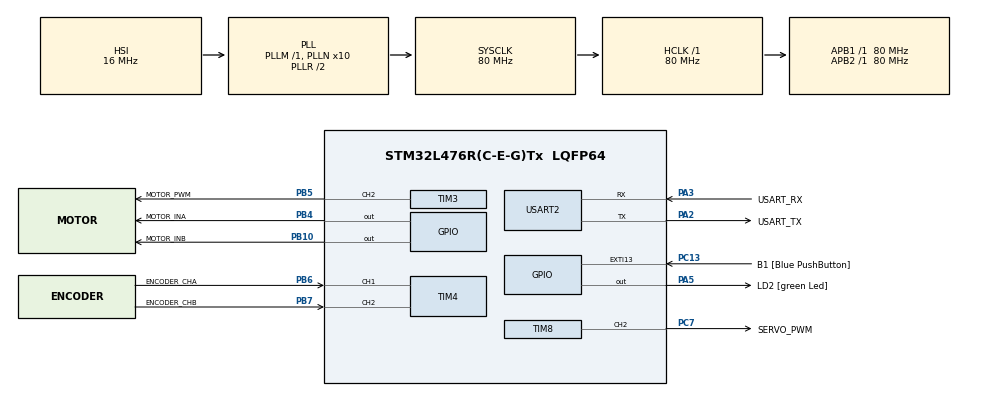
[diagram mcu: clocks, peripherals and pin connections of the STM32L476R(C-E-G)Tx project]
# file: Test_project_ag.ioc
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Dma.Request0=USART2_RX
Dma.Request1=USART2_TX
Dma.USART2_RX.0.Direction=DMA_PERIPH_TO_MEMORY
Dma.USART2_RX.0.Instance=DMA1_Channel6
Dma.USART2_RX.0.MemDataAlignment=DMA_MDATAALIGN_BYTE
Dma.USART2_RX.0.MemInc=DMA_MINC_ENABLE
Dma.USART2_RX.0.Mode=DMA_CIRCULAR
Dma.USART2_RX.0.PeriphDataAlignment=DMA_PDATAALIGN_BYTE
Dma.USART2_RX.0.PeriphInc=DMA_PINC_DISABLE
Dma.USART2_RX.0.Priority=DMA_PRIORITY_VERY_HIGH
Dma.USART2_TX.1.Direction=DMA_MEMORY_TO_PERIPH
Dma.USART2_TX.1.Instance=DMA1_Channel7
Dma.USART2_TX.1.MemDataAlignment=DMA_MDATAALIGN_BYTE
Dma.USART2_TX.1.MemInc=DMA_MINC_ENABLE
Dma.USART2_TX.1.Mode=DMA_NORMAL
Dma.USART2_TX.1.PeriphDataAlignment=DMA_PDATAALIGN_BYTE
Dma.USART2_TX.1.PeriphInc=DMA_PINC_DISABLE
Dma.USART2_TX.1.Priority=DMA_PRIORITY_HIGH
Mcu.Family=STM32L4
Mcu.Name=STM32L476R(C-E-G)Tx
Mcu.Package=LQFP64
Mcu.UserConstants=PUB_COUNT_MAX,9999;SERVO_PWM_COUNT_MAX,39999;SERVO_PRESCALER,39;ENC_COUNT_MAX,999;ENC_PRESCALER,79;RASPI_UART_BAUD,1000000;PUB_PRESCALER,79;MOT_PWM_COUNT_MAX,4999
NVIC.DMA1_Channel6_IRQn=true\:0\:0\:false\:false\:true\:false\:true\:true
NVIC.DMA1_Channel7_IRQn=true\:0\:0\:false\:false\:true\:false\:true\:true
NVIC.EXTI15_10_IRQn=true\:0\:0\:false\:false\:true\:true\:true\:true
NVIC.PriorityGroup=NVIC_PRIORITYGROUP_4
NVIC.TIM1_UP_TIM16_IRQn=true\:0\:0\:false\:false\:true\:true\:true\:true
NVIC.TIM6_DAC_IRQn=true\:0\:0\:false\:false\:true\:true\:true\:true
NVIC.USART2_IRQn=true\:0\:0\:false\:false\:true\:true\:true\:true
PA13\ (JTMS-SWDIO).GPIO_Label=TMS
PA13\ (JTMS-SWDIO).Mode=Serial_Wire
PA13\ (JTMS-SWDIO).Signal=SYS_JTMS-SWDIO
PA14\ (JTCK-SWCLK).GPIO_Label=TCK
PA14\ (JTCK-SWCLK).Mode=Serial_Wire
PA14\ (JTCK-SWCLK).Signal=SYS_JTCK-SWCLK
PA2.GPIO_Label=USART_TX
PA2.GPIO_Mode=GPIO_MODE_AF_PP
PA2.GPIO_PuPd=GPIO_NOPULL
PA2.GPIO_Speed=GPIO_SPEED_FREQ_VERY_HIGH
PA2.Mode=Asynchronous
PA2.Signal=USART2_TX
PA3.GPIO_Label=USART_RX
PA3.GPIO_Mode=GPIO_MODE_AF_PP
PA3.GPIO_PuPd=GPIO_NOPULL
PA3.GPIO_Speed=GPIO_SPEED_FREQ_VERY_HIGH
PA3.Mode=Asynchronous
PA3.Signal=USART2_RX
PA5.GPIO_Label=LD2 [green Led]
PA5.GPIO_ModeDefaultOutputPP=GPIO_MODE_OUTPUT_PP
PA5.GPIO_PuPd=GPIO_NOPULL
PA5.GPIO_Speed=GPIO_SPEED_FREQ_LOW
PA5.Signal=GPIO_Output
PB10.GPIO_Label=MOTOR_INB
PB10.Signal=GPIO_Output
PB3\ (JTDO-TRACESWO).GPIO_Label=SWO
PB3\ (JTDO-TRACESWO).Signal=SYS_JTDO-SWO
PB4\ (NJTRST).GPIO_Label=MOTOR_INA
PB4\ (NJTRST).Signal=GPIO_Output
PB5.GPIO_Label=MOTOR_PWM
PB5.Signal=S_TIM3_CH2
PB6.GPIO_FM6=I2C_FASTMODEPLUS_PB6
PB6.GPIO_Label=ENCODER_CHA
PB6.Signal=S_TIM4_CH1
PB7.GPIO_FM7=I2C_FASTMODEPLUS_PB7
PB7.GPIO_Label=ENCODER_CHB
PB7.Signal=S_TIM4_CH2
PC13.GPIO_Label=B1 [Blue PushButton]
PC13.GPIO_ModeDefaultEXTI=GPIO_MODE_IT_FALLING
PC13.GPIO_PuPd=GPIO_NOPULL
PC13.Signal=GPXTI13
PC14-OSC32_IN\ (PC14).Mode=LSE-External-Oscillator
PC14-OSC32_IN\ (PC14).Signal=RCC_OSC32_IN
PC15-OSC32_OUT\ (PC15).Mode=LSE-External-Oscillator
PC15-OSC32_OUT\ (PC15).Signal=RCC_OSC32_OUT
PC7.GPIO_Label=SERVO_PWM
PC7.Signal=S_TIM8_CH2
PH0-OSC_IN\ (PH0).Signal=RCC_OSC_IN
PH1-OSC_OUT\ (PH1).Signal=RCC_OSC_OUT
ProjectManager.HeapSize=0x200
ProjectManager.StackSize=0x400
ProjectManager.TargetToolchain=STM32CubeIDE
RCC.ADCFreq_Value=64000000
RCC.AHBFreq_Value=80000000
RCC.APB1Freq_Value=80000000
RCC.APB1TimFreq_Value=80000000
RCC.APB2Freq_Value=80000000
RCC.APB2TimFreq_Value=80000000
RCC.CortexFreq_Value=80000000
RCC.HCLKFreq_Value=80000000
RCC.HSE_VALUE=8000000
RCC.HSI_VALUE=16000000
RCC.MSI_VALUE=4000000
RCC.PLLN=10
RCC.PLLSourceVirtual=RCC_PLLSOURCE_HSI
RCC.PREFETCH_ENABLE=1
RCC.SYSCLKFreq_VALUE=80000000
RCC.SYSCLKSource=RCC_SYSCLKSOURCE_PLLCLK
RCC.USBFreq_Value=64000000
RCC.VCOOutputFreq_Value=160000000
SH.S_TIM3_CH2.0=TIM3_CH2,PWM Generation2 CH2
SH.S_TIM4_CH1.0=TIM4_CH1,Encoder_Interface
SH.S_TIM4_CH2.0=TIM4_CH2,Encoder_Interface
SH.S_TIM8_CH2.0=TIM8_CH2,PWM Generation2 CH2
TIM16.Period=ENC_COUNT_MAX
TIM16.Prescaler=ENC_PRESCALER
TIM3.Channel-PWM\ Generation2\ CH2=TIM_CHANNEL_2
TIM3.OCFastMode_PWM-PWM\ Generation2\ CH2=TIM_OCFAST_ENABLE
TIM3.Period=MOT_PWM_COUNT_MAX
TIM4.CounterMode=TIM_COUNTERMODE_UP
TIM4.EncoderMode=TIM_ENCODERMODE_TI1
TIM4.IC1Filter=15
TIM4.IC2Filter=15
TIM6.Period=PUB_COUNT_MAX
TIM6.Prescaler=PUB_PRESCALER
TIM8.Channel-PWM\ Generation2\ CH2=TIM_CHANNEL_2
TIM8.OCFastMode_PWM-PWM\ Generation2\ CH2=TIM_OCFAST_ENABLE
TIM8.Period=SERVO_PWM_COUNT_MAX
TIM8.Prescaler=SERVO_PRESCALER
USART2.BaudRate=RASPI_UART_BAUD
USART2.VirtualMode-Asynchronous=VM_ASYNC
VP_TIM16_VS_ClockSourceINT.Mode=Enable_Timer
VP_TIM6_VS_ClockSourceINT.Mode=Enable_Timer
board=NUCLEO-L476RG

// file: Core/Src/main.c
/* USER CODE BEGIN Header */
/**
  ******************************************************************************
  * @file           : main.c
  * @brief          : Main program body
  ******************************************************************************
  * @attention
  *
  * Copyright (c) 2022 STMicroelectronics.
  * All rights reserved.
  *
  * This software is licensed under terms that can be found in the LICENSE file
  * in the root directory of this software component.
  * If no LICENSE file comes with this software, it is provided AS-IS.
  *
  ******************************************************************************
  */
/* USER CODE END Header */
#include "main.h"
#include "dma.h"
#include "tim.h"
#include "usart.h"
#include "gpio.h"

/* USER CODE BEGIN Includes */
#include "mainpp.h"
#include "string.h"
/* USER CODE END Includes */

/* USER CODE BEGIN PV */

char *msg = "Hello Nucleo Fun!\n\r";

/* USER CODE END PV */

void SystemClock_Config(void);

int main(void)
{

  /* MCU Configuration--------------------------------------------------------*/

  /* Reset of all peripherals, Initializes the Flash interface and the Systick. */
  HAL_Init();

  /* Configure the system clock */
  SystemClock_Config();

  /* Initialize all configured peripherals */
  MX_GPIO_Init();
  MX_DMA_Init();
  MX_USART2_UART_Init();
  MX_TIM3_Init();
  MX_TIM4_Init();
  MX_TIM8_Init();
  MX_TIM16_Init();
  MX_TIM6_Init();
  /* USER CODE BEGIN 2 */
  setup();
  /* USER CODE END 2 */

  /* Infinite loop */
  while (1)
  {

    /* USER CODE BEGIN 3 */
	loop();
  }
  /* USER CODE END 3 */
}

void SystemClock_Config(void)
{
  RCC_OscInitTypeDef RCC_OscInitStruct = {0};
  RCC_ClkInitTypeDef RCC_ClkInitStruct = {0};

  /** Configure the main internal regulator output voltage
  */
  if (HAL_PWREx_ControlVoltageScaling(PWR_REGULATOR_VOLTAGE_SCALE1) != HAL_OK)
  {
    Error_Handler();
  }

  /** Initializes the RCC Oscillators according to the specified parameters
  * in the RCC_OscInitTypeDef structure.
  */
  RCC_OscInitStruct.OscillatorType = RCC_OSCILLATORTYPE_HSI;
  RCC_OscInitStruct.HSIState = RCC_HSI_ON;
  RCC_OscInitStruct.HSICalibrationValue = RCC_HSICALIBRATION_DEFAULT;
  RCC_OscInitStruct.PLL.PLLState = RCC_PLL_ON;
  RCC_OscInitStruct.PLL.PLLSource = RCC_PLLSOURCE_HSI;
  RCC_OscInitStruct.PLL.PLLM = 1;
  RCC_OscInitStruct.PLL.PLLN = 10;
  RCC_OscInitStruct.PLL.PLLP = RCC_PLLP_DIV7;
  RCC_OscInitStruct.PLL.PLLQ = RCC_PLLQ_DIV2;
  RCC_OscInitStruct.PLL.PLLR = RCC_PLLR_DIV2;
  if (HAL_RCC_OscConfig(&RCC_OscInitStruct) != HAL_OK)
  {
    Error_Handler();
  }

  /** Initializes the CPU, AHB and APB buses clocks
  */
  RCC_ClkInitStruct.ClockType = RCC_CLOCKTYPE_HCLK|RCC_CLOCKTYPE_SYSCLK
                              |RCC_CLOCKTYPE_PCLK1|RCC_CLOCKTYPE_PCLK2;
  RCC_ClkInitStruct.SYSCLKSource = RCC_SYSCLKSOURCE_PLLCLK;
  RCC_ClkInitStruct.AHBCLKDivider = RCC_SYSCLK_DIV1;
  RCC_ClkInitStruct.APB1CLKDivider = RCC_HCLK_DIV1;
  RCC_ClkInitStruct.APB2CLKDivider = RCC_HCLK_DIV1;

  if (HAL_RCC_ClockConfig(&RCC_ClkInitStruct, FLASH_LATENCY_4) != HAL_OK)
  {
    Error_Handler();
  }
}

void Error_Handler(void)
{
  __disable_irq();
  while (1)
  {
  }
}
